# PIC32MX534F064H register map
Vendor: Microchip
Registers are 32-bit, read-write, reset 0x0 unless marked. A register's access mark holds for its fields unless they carry their own. Addresses are absolute, and some are shared; only a register's first bit layout is shown; [hi:lo] are bit positions; {n}, {i} and the like mark numbered series.

## USB
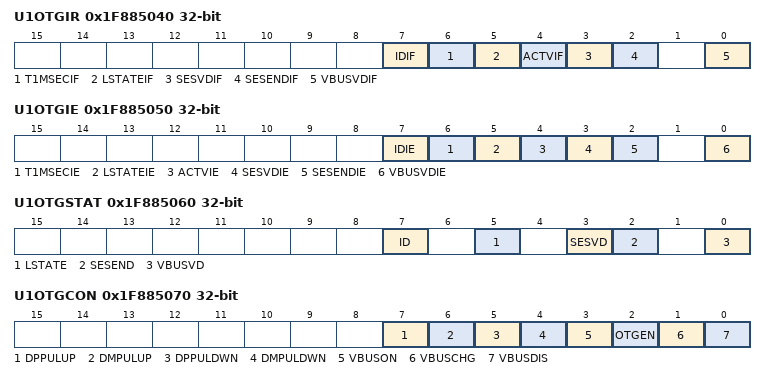
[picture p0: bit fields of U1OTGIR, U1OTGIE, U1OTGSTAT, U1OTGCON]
0x1F885040 U1OTGIR
  [7] IDIF, [6] T1MSECIF, [5] LSTATEIF, [4] ACTVIF, [3] SESVDIF, [2] SESENDIF, [0] VBUSVDIF
0x1F885050 U1OTGIE
  [7] IDIE, [6] T1MSECIE, [5] LSTATEIE, [4] ACTVIE, [3] SESVDIE, [2] SESENDIE, [0] VBUSVDIE
0x1F885060 U1OTGSTAT
  [7] ID, [5] LSTATE, [3] SESVD, [2] SESEND, [0] VBUSVD
0x1F885070 U1OTGCON
  [7] DPPULUP, [6] DMPULUP, [5] DPPULDWN, [4] DMPULDWN, [3] VBUSON, [2] OTGEN, [1] VBUSCHG, [0] VBUSDIS
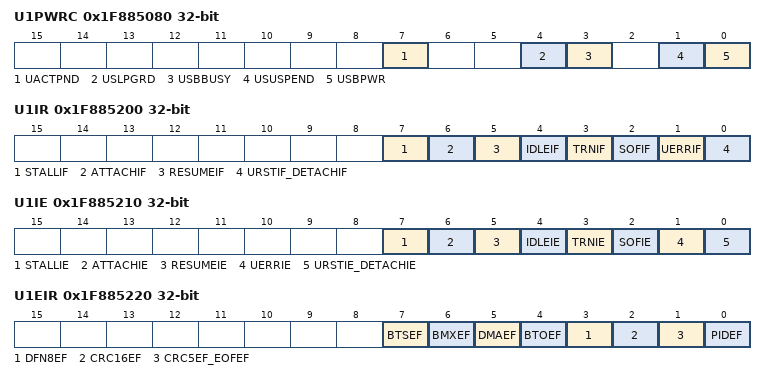
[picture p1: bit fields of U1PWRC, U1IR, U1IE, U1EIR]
0x1F885080 U1PWRC reset not defined — (power-on value ------------------------0--0x-00)
  [7] UACTPND ro, [4] USLPGRD, [3] USBBUSY, [1] USUSPEND, [0] USBPWR
0x1F885200 U1IR
  [7] STALLIF, [6] ATTACHIF, [5] RESUMEIF, [4] IDLEIF, [3] TRNIF, [2] SOFIF, [1] UERRIF, [0] URSTIF_DETACHIF
0x1F885210 U1IE
  [7] STALLIE, [6] ATTACHIE, [5] RESUMEIE, [4] IDLEIE, [3] TRNIE, [2] SOFIE, [1] UERRIE, [0] URSTIE_DETACHIE
0x1F885220 U1EIR
  [7] BTSEF, [6] BMXEF, [5] DMAEF, [4] BTOEF, [3] DFN8EF, [2] CRC16EF, [1] CRC5EF_EOFEF, [0] PIDEF
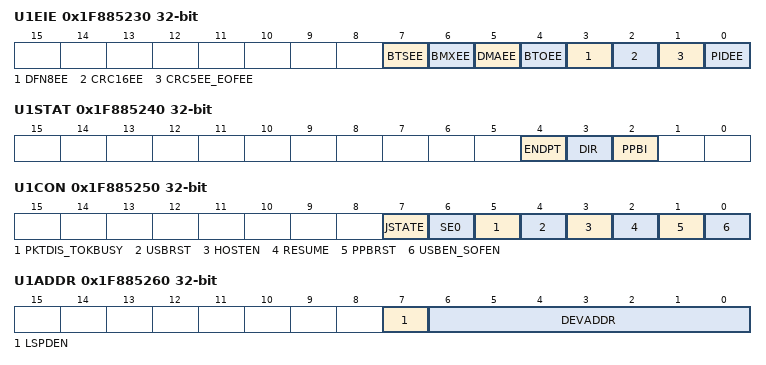
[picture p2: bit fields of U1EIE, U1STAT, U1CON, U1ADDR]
0x1F885230 U1EIE reset not defined — (power-on value ------------------------0000000x)
  [7] BTSEE, [6] BMXEE, [5] DMAEE, [4] BTOEE, [3] DFN8EE, [2] CRC16EE, [1] CRC5EE_EOFEE, [0] PIDEE
0x1F885240 U1STAT ro reset not defined
  [4] ENDPT, [3] DIR, [2] PPBI
0x1F885250 U1CON
  [7] JSTATE, [6] SE0, [5] PKTDIS_TOKBUSY, [4] USBRST, [3] HOSTEN, [2] RESUME, [1] PPBRST, [0] USBEN_SOFEN
0x1F885260 U1ADDR
  [7] LSPDEN, [6:0] DEVADDR
0x1F885270 U1BDTP1
  [7:1] BDTPTRL
0x1F885280 U1FRML ro reset not defined
  [7:0] FRML
0x1F885290 U1FRMH ro reset not defined
  [2:0] FRMH
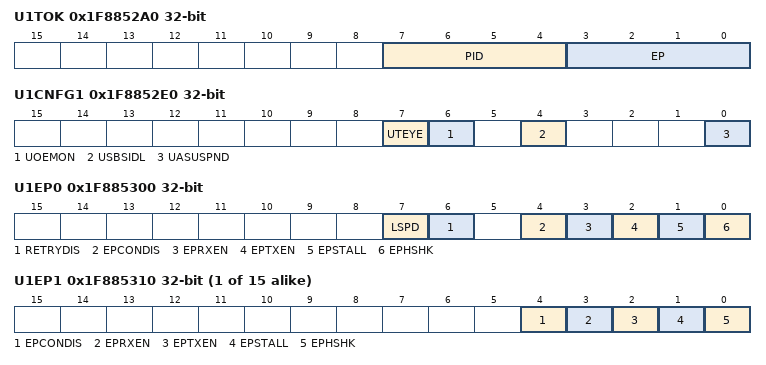
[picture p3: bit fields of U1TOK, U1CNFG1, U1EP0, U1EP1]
0x1F8852A0 U1TOK
  [7:4] PID, [3:0] EP
0x1F8852B0 U1SOF
  [7:0] CNT
0x1F8852C0 U1BDTP2
  [7:0] BDTPTRH
0x1F8852D0 U1BDTP3
  [7:0] BDTPTRU
0x1F8852E0 U1CNFG1 reset not defined — (power-on value ------------------------xxxx-00x)
  [7] UTEYE, [6] UOEMON, [4] USBSIDL, [0] UASUSPND
0x1F885300 U1EP0
  [7] LSPD, [6] RETRYDIS, [4] EPCONDIS, [3] EPRXEN, [2] EPTXEN, [1] EPSTALL, [0] EPHSHK
{0x1F885300+0x10*i} U1EP{i} (i=1..15)
  [4] EPCONDIS, [3] EPRXEN, [2] EPTXEN, [1] EPSTALL, [0] EPHSHK

## TDAA_Ports
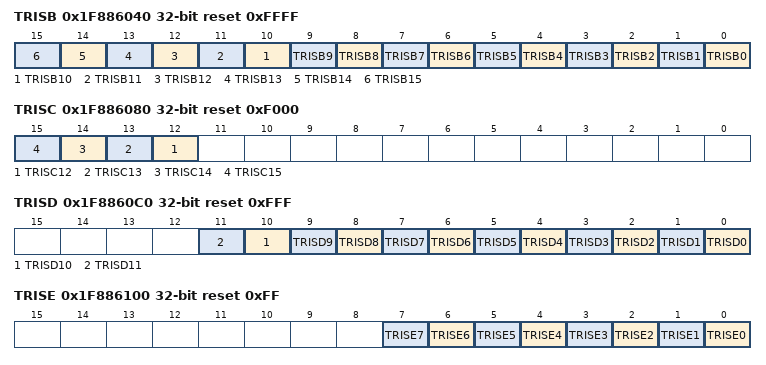
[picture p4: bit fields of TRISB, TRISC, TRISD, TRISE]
0x1F886040 TRISB reset 0xFFFF
  [n] TRISB{n} (n=0..15)
0x1F886080 TRISC reset 0xF000
  [n] TRISC{n} (n=12..15)
0x1F8860C0 TRISD reset 0xFFF
  [n] TRISD{n} (n=0..11)
0x1F886100 TRISE reset 0xFF
  [n] TRISE{n} (n=0..7)
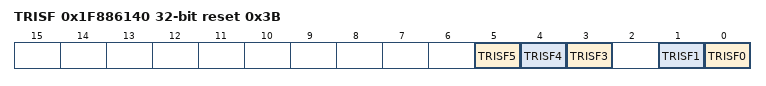
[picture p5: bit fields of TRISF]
0x1F886140 TRISF reset 0x3B
  [5] TRISF5, [4] TRISF4, [3] TRISF3, [1] TRISF1, [0] TRISF0

## PORTB
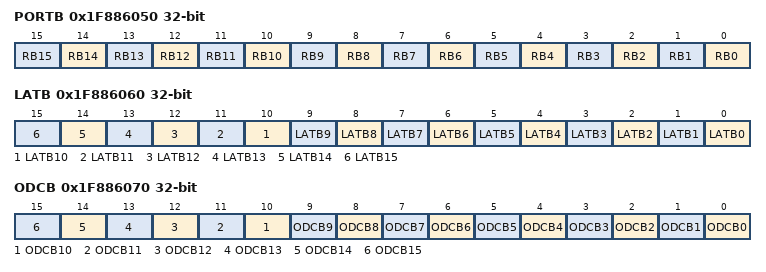
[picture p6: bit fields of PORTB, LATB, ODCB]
0x1F886050 PORTB reset not defined — (power-on value ----------------xxxxxxxxxxxxxxxx)
  [n] RB{n} (n=0..15)
0x1F886060 LATB reset not defined — (power-on value ----------------xxxxxxxxxxxxxxxx)
  [n] LATB{n} (n=0..15)
0x1F886070 ODCB
  [n] ODCB{n} (n=0..15)

## PORTC
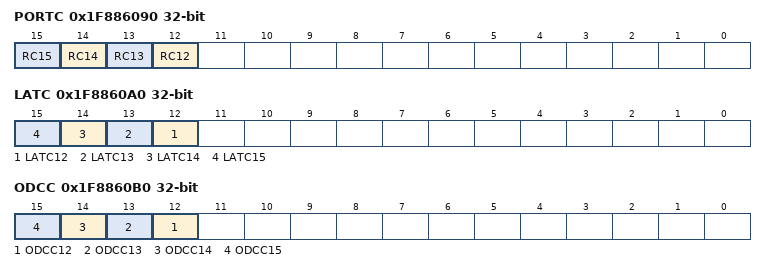
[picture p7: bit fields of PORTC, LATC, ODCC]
0x1F886090 PORTC reset not defined — (power-on value ----------------xxxx------------)
  [n] RC{n} (n=12..15)
0x1F8860A0 LATC reset not defined — (power-on value ----------------xxxx------------)
  [n] LATC{n} (n=12..15)
0x1F8860B0 ODCC
  [n] ODCC{n} (n=12..15)

## PORTD
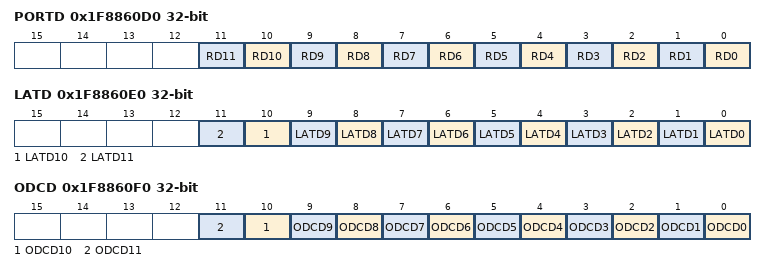
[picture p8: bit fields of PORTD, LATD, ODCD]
0x1F8860D0 PORTD reset not defined — (power-on value --------------------xxxxxxxxxxxx)
  [n] RD{n} (n=0..11)
0x1F8860E0 LATD reset not defined — (power-on value --------------------xxxxxxxxxxxx)
  [n] LATD{n} (n=0..11)
0x1F8860F0 ODCD
  [n] ODCD{n} (n=0..11)

## PORTE
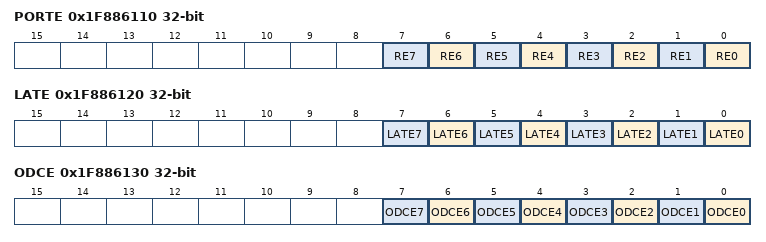
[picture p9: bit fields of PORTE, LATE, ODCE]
0x1F886110 PORTE reset not defined — (power-on value ------------------------xxxxxxxx)
  [n] RE{n} (n=0..7)
0x1F886120 LATE reset not defined — (power-on value ------------------------xxxxxxxx)
  [n] LATE{n} (n=0..7)
0x1F886130 ODCE
  [n] ODCE{n} (n=0..7)

## PORTF
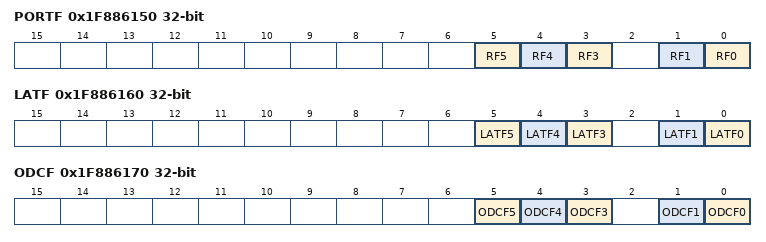
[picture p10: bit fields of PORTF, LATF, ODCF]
0x1F886150 PORTF reset not defined — (power-on value --------------------------xxx-xx)
  [5] RF5, [4] RF4, [3] RF3, [1] RF1, [0] RF0
0x1F886160 LATF reset not defined — (power-on value --------------------------xxx-xx)
  [5] LATF5, [4] LATF4, [3] LATF3, [1] LATF1, [0] LATF0
0x1F886170 ODCF
  [5] ODCF5, [4] ODCF4, [3] ODCF3, [1] ODCF1, [0] ODCF0

## TDAA_PortG
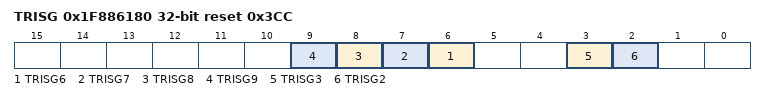
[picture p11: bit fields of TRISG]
0x1F886180 TRISG reset 0x3CC
  [n] TRISG{n} (n=6..9), [3] TRISG3, [2] TRISG2

## PORTG
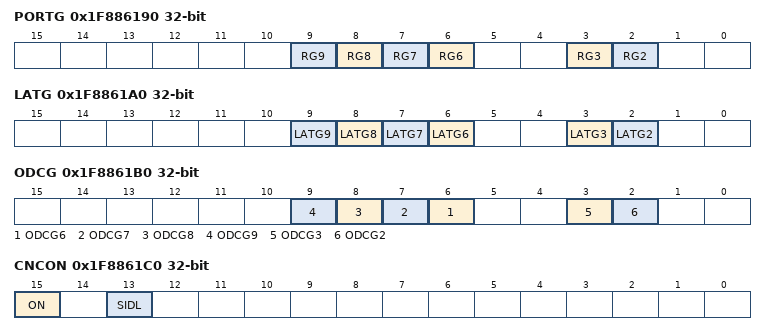
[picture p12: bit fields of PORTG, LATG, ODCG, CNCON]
0x1F886190 PORTG reset not defined — (power-on value ----------------------xxxx--xx--)
  [n] RG{n} (n=6..9), [3] RG3, [2] RG2
0x1F8861A0 LATG reset not defined — (power-on value ----------------------xxxx--xx--)
  [n] LATG{n} (n=6..9), [3] LATG3 ro, [2] LATG2 ro
0x1F8861B0 ODCG
  [n] ODCG{n} (n=6..9), [3] ODCG3 ro, [2] ODCG2 ro
0x1F8861C0 CNCON
  [15] ON, [13] SIDL
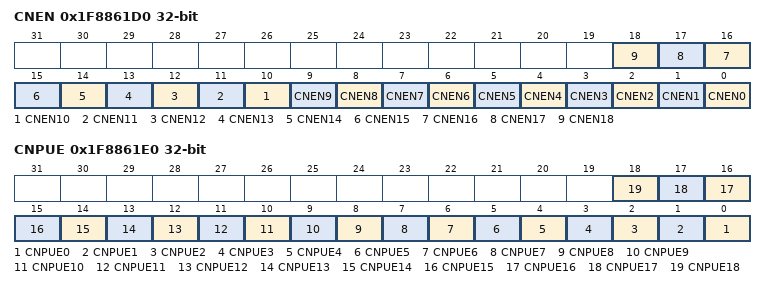
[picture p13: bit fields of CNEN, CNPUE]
0x1F8861D0 CNEN
  [n] CNEN{n} (n=0..18)
0x1F8861E0 CNPUE
  [n] CNPUE{n} (n=0..18)

## CAN1
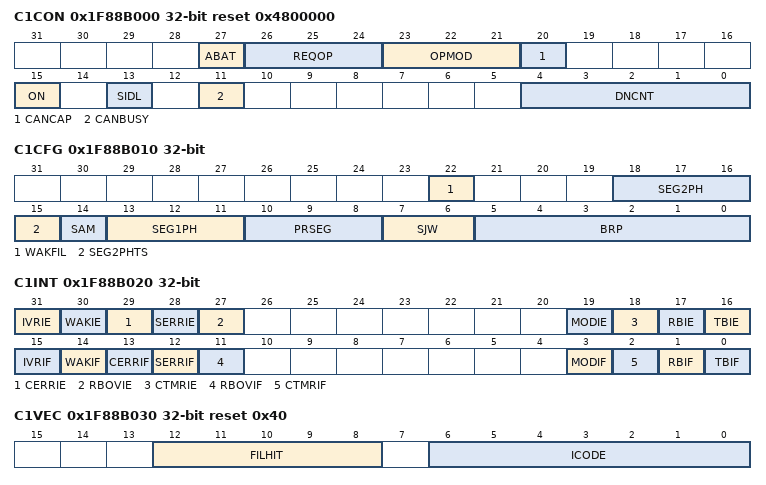
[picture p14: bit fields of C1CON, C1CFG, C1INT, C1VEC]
0x1F88B000 C1CON reset 0x4800000
  [27] ABAT — (can only be set)
  [26:24] REQOP
  [23:21] OPMOD ro
  [20] CANCAP
  [15] ON
  [13] SIDL
  [11] CANBUSY ro
  [4:0] DNCNT
0x1F88B010 C1CFG
  [22] WAKFIL, [18:16] SEG2PH, [15] SEG2PHTS, [14] SAM, [13:11] SEG1PH, [10:8] PRSEG, [7:6] SJW, [5:0] BRP
0x1F88B020 C1INT
  [31] IVRIE, [30] WAKIE, [29] CERRIE, [28] SERRIE, [27] RBOVIE, [19] MODIE, [18] CTMRIE, [17] RBIE, [16] TBIE, [15] IVRIF, [14] WAKIF, [13] CERRIF, [12] SERRIF, [11] RBOVIF, [3] MODIF, [2] CTMRIF, [1] RBIF, [0] TBIF
0x1F88B030 C1VEC ro reset 0x40
  [12:8] FILHIT, [6:0] ICODE
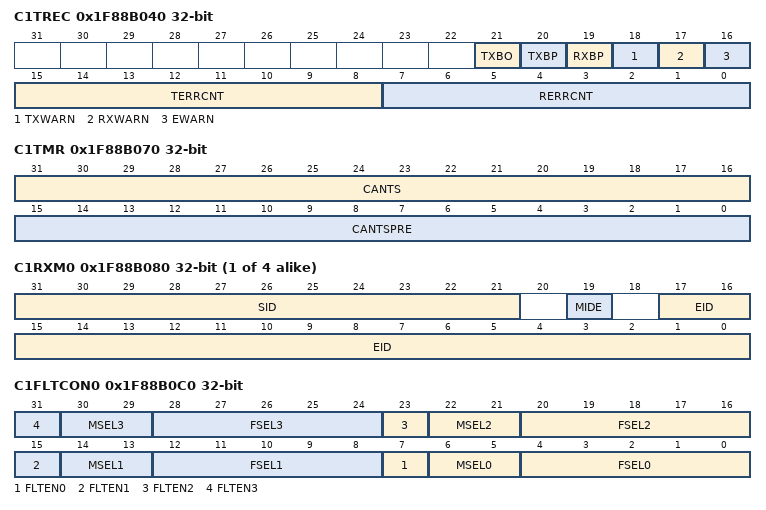
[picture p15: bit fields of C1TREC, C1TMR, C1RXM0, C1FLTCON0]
0x1F88B040 C1TREC ro
  [21] TXBO, [20] TXBP, [19] RXBP, [18] TXWARN, [17] RXWARN, [16] EWARN, [15:8] TERRCNT, [7:0] RERRCNT
0x1F88B050 C1FSTAT ro
  [31:0] FIFOIP
0x1F88B060 C1RXOVF ro
  [31:0] RXOVF
0x1F88B070 C1TMR
  [31:16] CANTS, [15:0] CANTSPRE
{0x1F88B080+0x10*i} C1RXM{i} (i=0..3)
  [31:21] SID, [19] MIDE, [17:0] EID
0x1F88B0C0 C1FLTCON0
  [8n+7] FLTEN{n} (n=0..3), [8n+6:8n+5] MSEL{n} (n=0..3), [8n+4:8n] FSEL{n} (n=0..3)
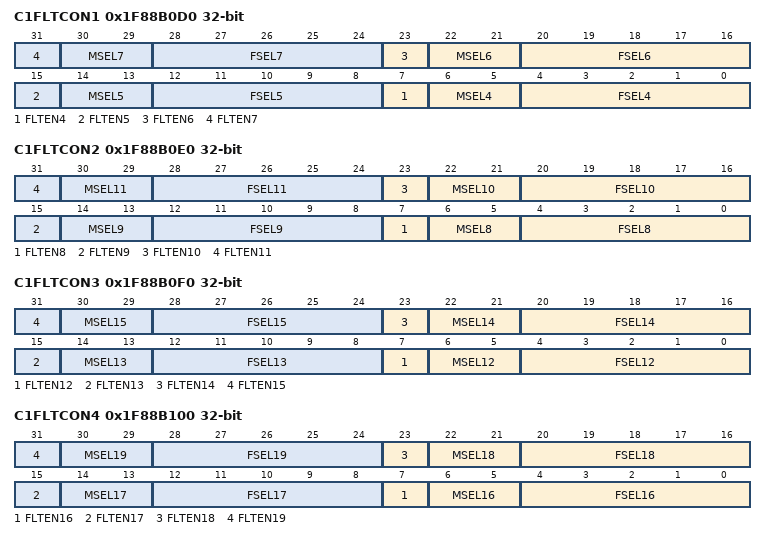
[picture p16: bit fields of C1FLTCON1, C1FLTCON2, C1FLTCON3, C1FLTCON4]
0x1F88B0D0 C1FLTCON1
  [8n-25] FLTEN{n} (n=4..7), [8n-26:8n-27] MSEL{n} (n=4..7), [8n-28:8n-32] FSEL{n} (n=4..7)
0x1F88B0E0 C1FLTCON2
  [8n-57] FLTEN{n} (n=8..11), [8n-58:8n-59] MSEL{n} (n=8..11), [8n-60:8n-64] FSEL{n} (n=8..11)
0x1F88B0F0 C1FLTCON3
  [8n-89] FLTEN{n} (n=12..15), [8n-90:8n-91] MSEL{n} (n=12..15), [8n-92:8n-96] FSEL{n} (n=12..15)
0x1F88B100 C1FLTCON4
  [8n-121] FLTEN{n} (n=16..19), [8n-122:8n-123] MSEL{n} (n=16..19), [8n-124:8n-128] FSEL{n} (n=16..19)
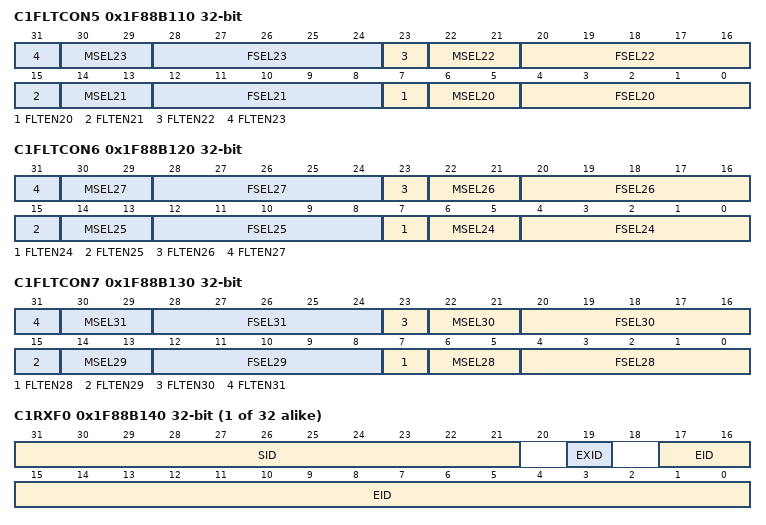
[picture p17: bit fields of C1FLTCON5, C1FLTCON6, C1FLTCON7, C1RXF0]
0x1F88B110 C1FLTCON5
  [8n-153] FLTEN{n} (n=20..23), [8n-154:8n-155] MSEL{n} (n=20..23), [8n-156:8n-160] FSEL{n} (n=20..23)
0x1F88B120 C1FLTCON6
  [8n-185] FLTEN{n} (n=24..27), [8n-186:8n-187] MSEL{n} (n=24..27), [8n-188:8n-192] FSEL{n} (n=24..27)
0x1F88B130 C1FLTCON7
  [8n-217] FLTEN{n} (n=28..31), [8n-218:8n-219] MSEL{n} (n=28..31), [8n-220:8n-224] FSEL{n} (n=28..31)
{0x1F88B140+0x10*i} C1RXF{i} reset not defined (i=0..31) — (power-on value xxxxxxxxxxx0x0xxxxxxxxxxxxxxxxxx)
  [31:21] SID, [19] EXID, [17:0] EID
0x1F88B340 C1FIFOBA
  [31:2] FIFOBA
{0x1F88B350+0x40*i} C1FIFOCON{i} (i=0..31)
  [20:16] FSIZE, [14] FRESET, [13] UINC, [12] DONLY, [7] TXEN, [6] TXABAT, [5] TXLARB, [4] TXERR, [3] TXREQ, [2] RTREN, [1:0] TXPRI
{0x1F88B360+0x40*i} C1FIFOINT{i} (i=0..31)
  [26] TXNFULLIE, [25] TXHALFIE, [24] TXEMPTYIE, [19] RXOVFLIE, [18] RXFULLIE, [17] RXHALFIE, [16] RXNEMPTYIE, [10] TXNFULLIF ro, [9] TXHALFIF ro, [8] TXEMPTYIF ro, [3] RXOVFLIF, [2] RXFULLIF ro, [1] RXHALFIF ro, [0] RXNEMPTYIF ro
{0x1F88B370+0x40*i} C1FIFOUA{i} ro reset not defined (i=0..31) — (power-on value xxxxxxxxxxxxxxxxxxxxxxxxxxxxxx00)
  [31:2] FIFOUA
{0x1F88B380+0x40*i} C1FIFOCI{i} ro (i=0..31)
  [4:0] CFIFOCI
